# STM32H503 register map
File version: 1.5
CPU: CM33 r0p0, little endian, MPU, FPU, 4 interrupt priority bits
Registers are 32-bit, read-write, reset 0x0 unless marked. A register's access mark holds for its fields unless they carry their own. Offsets are from the block's base; [hi:lo] are bit positions; {n}, {i} and the like mark numbered series.

## COMP — Comparator
Base 0x40004000
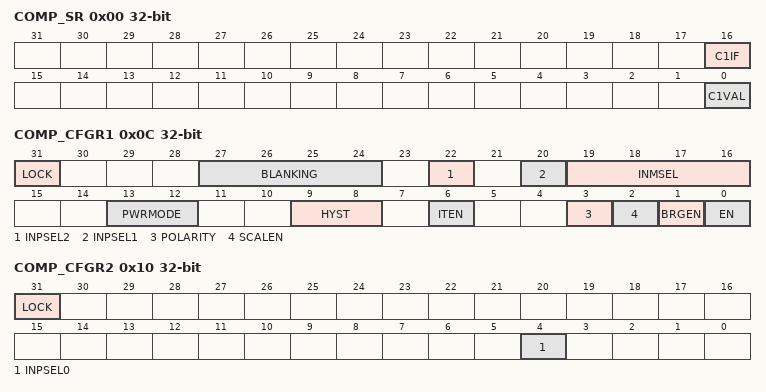
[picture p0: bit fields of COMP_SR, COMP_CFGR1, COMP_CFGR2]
0x00 COMP_SR ro — Comparator status register
  [16] C1IF — COMP Channel1 interrupt flag This bit is set by hardware when the COMP Channel1 output is set This bit is cleared by software writing 1 the CC1IF bit in the COMP_ICFR register.
  [0] C1VAL — COMP Channel1 output status bit This bit is read-only. It reflects the current COMP Channel1 output taking into account POLARITY and BLANKING bits effect.
0x04 COMP_ICFR — Comparator interrupt clear flag register
  [16] CC1IF — Clear COMP Channel1 interrupt flag Writing 1 clears the C1IF flag in the COMP_SR register.
0x0C COMP_CFGR1 — Comparator configuration register 1
  [31] LOCK — Lock This bit is set by software and cleared by a hardware system reset. It locks the whole content of the COMP Channel1 configuration register COMP_CFGR1[31:0]
    0=COMP_CFGR1[31:0] register is read/write; 1=COMP_CFGR1[31:0] is read-only
  [27:24] BLANKING — COMP Channel1 blanking source selection Bits of this field are set and cleared by software (only if LOCK not set). The field selects the input source for COMP Channel1 output blanking: All other values: reserved
    0=No blanking; {v}=comp_blk{v} (v=1..6)
  [22] INPSEL2 — COMP noninverting input selection This bit is set and cleared by software (only if LOCK not set). They select which input is connected to the positive input of the COMP channel. See Table 145: COMP1 noninverting input assignment for more details.
  [20] INPSEL1 — COMP noninverting input selection This bit is set and cleared by software (only if LOCK not set). They select which input is connected to the positive input of COMP channel. Note: See Table 145: COMP1 noninverting input assignment for more details.
  [19:16] INMSEL — COMP channel1 inverting input selection These bits are set and cleared by software (only if LOCK not set). They select which input is connected to the input minus of the COMP channel. Note: See Table 146: COMP1 inverting input assignment for more details.
  [13:12] PWRMODE — Power mode of the COMP channel1 These bits are set and cleared by software (only if LOCK not set). They control the power/speed of the COMP channel1.
    0=High speed/high power; 1=Medium speed/medium power; 2=Medium speed/medium power; 3=Ultra low power/ultra-low-power
  [9:8] HYST — COMP channel1 hysteresis selection These bits are set and cleared by software (only if LOCK not set). They select the hysteresis voltage of the COMP channel1.
    0=No hysteresis; 1=Low hysteresis; 2=Medium hysteresis; 3=High hysteresis
  [6] ITEN — COMP channel1 interrupt enable This bit is set and cleared by software (only if LOCK not set). This bit enable the interrupt generation of the COMP channel1.
    0=Interrupt generation disabled for COMP channel1; 1=Interrupt generation enabled for COMP channel1
  [3] POLARITY — COMP channel1 polarity selection This bit is set and cleared by software (only if LOCK not set). It inverts COMP channel1 polarity.
    0=COMP channel1 output is not inverted; 1=COMP Channel1 output is inverted
  [2] SCALEN — Voltage scaler enable This bit is set and cleared by software (only if LOCK not set). This bit enables the V REFINT scaler for the COMP channels.
    0=V REFINT scaler disabled; 1=V REFINT scaler enabled
  [1] BRGEN — Scaler bridge enable This bit is set and cleared by software (only if LOCK not set). This bit enables the bridge of the scaler. If SCALEN is set and BRGEN is reset, all four scaler outputs provide the same level V REF_COMP (similar to V REFINT ). If SCALEN and BRGEN are set, the four scaler outputs provide V REF_COMP , 3/4 V REF_COMP , 1/2 V REF_COMP and 1/4 V REF_COMP levels, respectively.
    0=Scaler resistor bridge disabled; 1=Scaler resistor bridge enabled
  [0] EN — COMP Channel1 enable This bit is set and cleared by software (only if LOCK not set). It enables the COMP Channel1.
    0=Disable; 1=Enable
0x10 COMP_CFGR2 — Comparator configuration register 2
  [31] LOCK — Lock This bit is set by software and cleared by a hardware system reset. It locks the whole content of the COMP Channel1 configuration register COMP_CFGR2[31:0]
    0=COMP_CFGR2[31:0] register is read/write; 1=COMP_CFGR2[31:0] is read-only
  [4] INPSEL0 — COMP non-inverting input selection This bit is set and cleared by software (only if LOCK not set). They select which input is connected to the positive input of COMP channel. See Table 145: COMP1 noninverting input assignment for more details.
